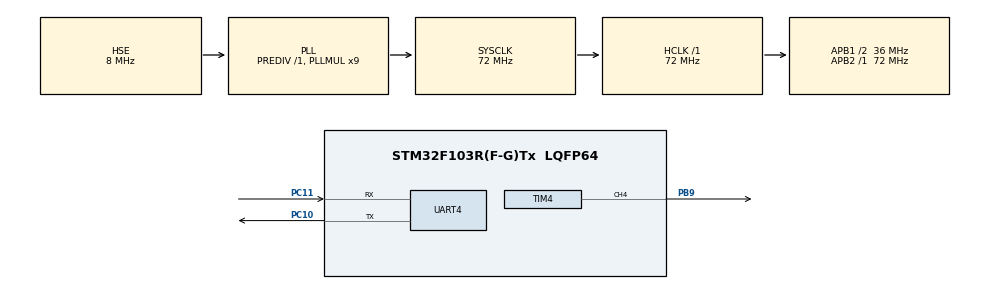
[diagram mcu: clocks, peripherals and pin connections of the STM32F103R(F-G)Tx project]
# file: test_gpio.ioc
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ADC1.Channel-0\#ChannelRegularConversion=ADC_CHANNEL_TEMPSENSOR
ADC1.NbrOfConversionFlag=1
ADC1.Rank-0\#ChannelRegularConversion=1
ADC1.SamplingTime-0\#ChannelRegularConversion=ADC_SAMPLETIME_1CYCLE_5
ADC1.master=1
Dma.Request0=UART4_RX
Dma.Request1=UART4_TX
Dma.UART4_RX.0.Direction=DMA_PERIPH_TO_MEMORY
Dma.UART4_RX.0.Instance=DMA2_Channel3
Dma.UART4_RX.0.MemDataAlignment=DMA_MDATAALIGN_BYTE
Dma.UART4_RX.0.MemInc=DMA_MINC_ENABLE
Dma.UART4_RX.0.Mode=DMA_CIRCULAR
Dma.UART4_RX.0.PeriphDataAlignment=DMA_PDATAALIGN_BYTE
Dma.UART4_RX.0.PeriphInc=DMA_PINC_DISABLE
Dma.UART4_RX.0.Priority=DMA_PRIORITY_LOW
Dma.UART4_TX.1.Direction=DMA_MEMORY_TO_PERIPH
Dma.UART4_TX.1.Instance=DMA2_Channel5
Dma.UART4_TX.1.MemDataAlignment=DMA_MDATAALIGN_BYTE
Dma.UART4_TX.1.MemInc=DMA_MINC_ENABLE
Dma.UART4_TX.1.Mode=DMA_NORMAL
Dma.UART4_TX.1.PeriphDataAlignment=DMA_PDATAALIGN_BYTE
Dma.UART4_TX.1.PeriphInc=DMA_PINC_DISABLE
Dma.UART4_TX.1.Priority=DMA_PRIORITY_LOW
Mcu.Family=STM32F1
Mcu.Name=STM32F103R(F-G)Tx
Mcu.Package=LQFP64
NVIC.DMA2_Channel3_IRQn=true\:0\:0\:false\:false\:true\:false\:true\:true
NVIC.DMA2_Channel4_5_IRQn=true\:0\:0\:false\:false\:true\:false\:true\:true
NVIC.PriorityGroup=NVIC_PRIORITYGROUP_4
NVIC.TIM4_IRQn=true\:0\:0\:false\:false\:true\:true\:true\:true
NVIC.UART4_IRQn=true\:0\:0\:false\:false\:true\:true\:true\:true
PA13.Mode=Serial_Wire
PA13.Signal=SYS_JTMS-SWDIO
PA14.Mode=Serial_Wire
PA14.Signal=SYS_JTCK-SWCLK
PB9.Signal=S_TIM4_CH4
PC10.Mode=Asynchronous
PC10.Signal=UART4_TX
PC11.Mode=Asynchronous
PC11.Signal=UART4_RX
PD0-OSC_IN.Mode=HSE-External-Oscillator
PD0-OSC_IN.Signal=RCC_OSC_IN
PD1-OSC_OUT.Mode=HSE-External-Oscillator
PD1-OSC_OUT.Signal=RCC_OSC_OUT
ProjectManager.HeapSize=0x800
ProjectManager.StackSize=0x1000
ProjectManager.TargetToolchain=STM32CubeIDE
RCC.ADCPresc=RCC_ADCPCLK2_DIV6
RCC.AHBFreq_Value=72000000
RCC.APB1CLKDivider=RCC_HCLK_DIV2
RCC.APB1Freq_Value=36000000
RCC.APB1TimFreq_Value=72000000
RCC.APB2Freq_Value=72000000
RCC.APB2TimFreq_Value=72000000
RCC.HCLKFreq_Value=72000000
RCC.PLLMUL=RCC_PLL_MUL9
RCC.PLLSourceVirtual=RCC_PLLSOURCE_HSE
RCC.SYSCLKFreq_VALUE=72000000
RCC.SYSCLKSource=RCC_SYSCLKSOURCE_PLLCLK
RCC.USBFreq_Value=72000000
SH.S_TIM4_CH4.0=TIM4_CH4,Output Compare4 CH4
TIM4.Channel-Output\ Compare4\ CH4=TIM_CHANNEL_4
TIM4.OC4Preload=DISABLE
TIM4.OCMode_4=TIM_OCMODE_TOGGLE
TIM4.OCPolarity_4=TIM_OCPOLARITY_LOW
TIM4.Period=9999
TIM4.Prescaler=7199
TIM4.Pulse-Output\ Compare4\ CH4=5000
UART4.VirtualMode=Asynchronous
VP_ADC1_TempSens_Input.Mode=IN-TempSens
VP_TIM4_VS_ClockSourceINT.Mode=Internal
board=custom

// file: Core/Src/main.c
/* USER CODE BEGIN Header */
/**
  ******************************************************************************
  * @file           : main.c
  * @brief          : Main program body
  ******************************************************************************
  * @attention
  *
  * Copyright (c) 2026 STMicroelectronics.
  * All rights reserved.
  *
  * This software is licensed under terms that can be found in the LICENSE file
  * in the root directory of this software component.
  * If no LICENSE file comes with this software, it is provided AS-IS.
  *
  ******************************************************************************
  */
/* USER CODE END Header */
#include "main.h"

/* USER CODE BEGIN Includes */
#include <stdio.h>
#include "my_own.h"
/* USER CODE END Includes */

/* USER CODE BEGIN PD */

int tx_ready = 1;
int rx_ready = 0;
uint16_t rx_length = 0;
int uart4_idle = 0;
uint8_t rx_buffer[10];
uint8_t tx_buffer[10];

/* USER CODE END PD */

ADC_HandleTypeDef hadc1;

TIM_HandleTypeDef htim4;

UART_HandleTypeDef huart4;
DMA_HandleTypeDef hdma_uart4_rx;
DMA_HandleTypeDef hdma_uart4_tx;

void SystemClock_Config(void);
static void MX_GPIO_Init(void);
static void MX_DMA_Init(void);
static void MX_UART4_Init(void);
static void MX_ADC1_Init(void);
static void MX_TIM4_Init(void);

int main(void)
{

  /* MCU Configuration--------------------------------------------------------*/

  /* Reset of all peripherals, Initializes the Flash interface and the Systick. */
  HAL_Init();

  /* Configure the system clock */
  SystemClock_Config();

  /* Initialize all configured peripherals */
  MX_GPIO_Init();
  MX_DMA_Init();
  MX_UART4_Init();
  MX_ADC1_Init();
  MX_TIM4_Init();

  /* Infinite loop */
  /* USER CODE BEGIN WHILE */
  const char* msg = "hello from chao dma1\n\r";

//   HAL_UART_Receive_DMA(&huart4, rx_buffer, 10);
//  __HAL_UART_ENABLE_IT(&huart4, UART_IT_IDLE);
   HAL_UARTEx_ReceiveToIdle_DMA(&huart4, rx_buffer, 10);
//   __HAL_DMA_DISABLE_IT(huart4.hdmarx, DMA_IT_HT);

//   start_timer(&htim4);
   HAL_TIM_OC_Start(&htim4, TIM_CHANNEL_4);
  while (1)
  {
    /* USER CODE END WHILE */

    /* USER CODE BEGIN 3 */
//	  static int i = 0;
//
//	  adc_start(&hadc1);
//
//	  gpio_toggle(GPIOB, GPIO_PIN_9);
//
//	  uint32_t value = convert_to_value(adc_read(&hadc1));
//	  uint32_t temp = get_temp(value);
//	  uint32_t x = temp/100;
//	  uint32_t z = temp%100;
//	  printf("chao: %lu.%lu\r\n",x,z);
//	  adc_start(&hadc1);
	  delay(1000);

//	//	  ++i;
//	//	 	 HAL_UART_Transmit(&huart4, (const uint8_t*)(msg), strlen(msg), 100);
//	//	 		  // Receive data: waits up to 1000ms for 10 bytes
//	////	 		  HAL_UART_Receive(&huart4, rx_buffer, 10, 10000);
//	////	 		  HAL_UART_Transmit(&huart4, rx_buffer, 10, 100);
//			 if (tx_ready)
//			 {
//				tx_ready = 0;
//			//	snprintf(tx_buffer, 10, "c:%f\n\r", 2.3f);
//				printf("chao %f\r\n",18.8);
//				printf("chao %d\r\n",18);
//	//	 		 HAL_UART_Transmit(&huart4, "x", 1, 10);
//	//	 		HAL_UART_Transmit_DMA(&huart4, (uint8_t*)tx_buffer, 10);
//				HAL_UART_Transmit_DMA(&huart4, (uint8_t*)msg, strlen(msg));
//			 }
//	//	 	 if (rx_ready && rx_length != 0)
//	//	 	 {
//	//	 		rx_ready = 0;
//	//	 		HAL_UART_Transmit_DMA(&huart4, (uint8_t*)tx_buffer, rx_length);
//	//	 	 }
//
//		  HAL_GPIO_WritePin(GPIOB, GPIO_PIN_9, GPIO_PIN_SET);

  }
  /* USER CODE END 3 */
}

void SystemClock_Config(void)
{
  RCC_OscInitTypeDef RCC_OscInitStruct = {0};
  RCC_ClkInitTypeDef RCC_ClkInitStruct = {0};
  RCC_PeriphCLKInitTypeDef PeriphClkInit = {0};

  /** Initializes the RCC Oscillators according to the specified parameters
  * in the RCC_OscInitTypeDef structure.
  */
  RCC_OscInitStruct.OscillatorType = RCC_OSCILLATORTYPE_HSE;
  RCC_OscInitStruct.HSEState = RCC_HSE_ON;
  RCC_OscInitStruct.HSEPredivValue = RCC_HSE_PREDIV_DIV1;
  RCC_OscInitStruct.HSIState = RCC_HSI_ON;
  RCC_OscInitStruct.PLL.PLLState = RCC_PLL_ON;
  RCC_OscInitStruct.PLL.PLLSource = RCC_PLLSOURCE_HSE;
  RCC_OscInitStruct.PLL.PLLMUL = RCC_PLL_MUL9;
  if (HAL_RCC_OscConfig(&RCC_OscInitStruct) != HAL_OK)
  {
    Error_Handler();
  }

  /** Initializes the CPU, AHB and APB buses clocks
  */
  RCC_ClkInitStruct.ClockType = RCC_CLOCKTYPE_HCLK|RCC_CLOCKTYPE_SYSCLK
                              |RCC_CLOCKTYPE_PCLK1|RCC_CLOCKTYPE_PCLK2;
  RCC_ClkInitStruct.SYSCLKSource = RCC_SYSCLKSOURCE_PLLCLK;
  RCC_ClkInitStruct.AHBCLKDivider = RCC_SYSCLK_DIV1;
  RCC_ClkInitStruct.APB1CLKDivider = RCC_HCLK_DIV2;
  RCC_ClkInitStruct.APB2CLKDivider = RCC_HCLK_DIV1;

  if (HAL_RCC_ClockConfig(&RCC_ClkInitStruct, FLASH_LATENCY_2) != HAL_OK)
  {
    Error_Handler();
  }
  PeriphClkInit.PeriphClockSelection = RCC_PERIPHCLK_ADC;
  PeriphClkInit.AdcClockSelection = RCC_ADCPCLK2_DIV6;
  if (HAL_RCCEx_PeriphCLKConfig(&PeriphClkInit) != HAL_OK)
  {
    Error_Handler();
  }
}

static void MX_ADC1_Init(void)
{

  ADC_ChannelConfTypeDef sConfig = {0};

  /** Common config
  */
  hadc1.Instance = ADC1;
  hadc1.Init.ScanConvMode = ADC_SCAN_DISABLE;
  hadc1.Init.ContinuousConvMode = DISABLE;
  hadc1.Init.DiscontinuousConvMode = DISABLE;
  hadc1.Init.ExternalTrigConv = ADC_SOFTWARE_START;
  hadc1.Init.DataAlign = ADC_DATAALIGN_RIGHT;
  hadc1.Init.NbrOfConversion = 1;
  if (HAL_ADC_Init(&hadc1) != HAL_OK)
  {
    Error_Handler();
  }

  /** Configure Regular Channel
  */
  sConfig.Channel = ADC_CHANNEL_TEMPSENSOR;
  sConfig.Rank = ADC_REGULAR_RANK_1;
  sConfig.SamplingTime = ADC_SAMPLETIME_1CYCLE_5;
  if (HAL_ADC_ConfigChannel(&hadc1, &sConfig) != HAL_OK)
  {
    Error_Handler();
  }

}

static void MX_TIM4_Init(void)
{

  TIM_ClockConfigTypeDef sClockSourceConfig = {0};
  TIM_MasterConfigTypeDef sMasterConfig = {0};
  TIM_OC_InitTypeDef sConfigOC = {0};

  htim4.Instance = TIM4;
  htim4.Init.Prescaler = 7199;
  htim4.Init.CounterMode = TIM_COUNTERMODE_UP;
  htim4.Init.Period = 9999;
  htim4.Init.ClockDivision = TIM_CLOCKDIVISION_DIV1;
  htim4.Init.AutoReloadPreload = TIM_AUTORELOAD_PRELOAD_DISABLE;
  if (HAL_TIM_Base_Init(&htim4) != HAL_OK)
  {
    Error_Handler();
  }
  sClockSourceConfig.ClockSource = TIM_CLOCKSOURCE_INTERNAL;
  if (HAL_TIM_ConfigClockSource(&htim4, &sClockSourceConfig) != HAL_OK)
  {
    Error_Handler();
  }
  if (HAL_TIM_OC_Init(&htim4) != HAL_OK)
  {
    Error_Handler();
  }
  sMasterConfig.MasterOutputTrigger = TIM_TRGO_RESET;
  sMasterConfig.MasterSlaveMode = TIM_MASTERSLAVEMODE_DISABLE;
  if (HAL_TIMEx_MasterConfigSynchronization(&htim4, &sMasterConfig) != HAL_OK)
  {
    Error_Handler();
  }
  sConfigOC.OCMode = TIM_OCMODE_TOGGLE;
  sConfigOC.Pulse = 5000;
  sConfigOC.OCPolarity = TIM_OCPOLARITY_LOW;
  sConfigOC.OCFastMode = TIM_OCFAST_DISABLE;
  if (HAL_TIM_OC_ConfigChannel(&htim4, &sConfigOC, TIM_CHANNEL_4) != HAL_OK)
  {
    Error_Handler();
  }
  HAL_TIM_MspPostInit(&htim4);

}

static void MX_UART4_Init(void)
{

  huart4.Instance = UART4;
  huart4.Init.BaudRate = 115200;
  huart4.Init.WordLength = UART_WORDLENGTH_8B;
  huart4.Init.StopBits = UART_STOPBITS_1;
  huart4.Init.Parity = UART_PARITY_NONE;
  huart4.Init.Mode = UART_MODE_TX_RX;
  huart4.Init.HwFlowCtl = UART_HWCONTROL_NONE;
  huart4.Init.OverSampling = UART_OVERSAMPLING_16;
  if (HAL_UART_Init(&huart4) != HAL_OK)
  {
    Error_Handler();
  }

}

static void MX_DMA_Init(void)
{

  /* DMA controller clock enable */
  __HAL_RCC_DMA2_CLK_ENABLE();

  /* DMA interrupt init */
  /* DMA2_Channel3_IRQn interrupt configuration */
  HAL_NVIC_SetPriority(DMA2_Channel3_IRQn, 0, 0);
  HAL_NVIC_EnableIRQ(DMA2_Channel3_IRQn);
  /* DMA2_Channel4_5_IRQn interrupt configuration */
  HAL_NVIC_SetPriority(DMA2_Channel4_5_IRQn, 0, 0);
  HAL_NVIC_EnableIRQ(DMA2_Channel4_5_IRQn);

}

static void MX_GPIO_Init(void)
{

  /* GPIO Ports Clock Enable */
  __HAL_RCC_GPIOD_CLK_ENABLE();
  __HAL_RCC_GPIOA_CLK_ENABLE();
  __HAL_RCC_GPIOC_CLK_ENABLE();
  __HAL_RCC_GPIOB_CLK_ENABLE();

}

/* USER CODE BEGIN 4 */
void HAL_UART_TxCpltCallback(UART_HandleTypeDef *huart) {
    if (huart->Instance == UART4) {
        tx_ready = 1; // Hardware is free again!
    }
}
//void HAL_UART_RxCpltCallback(UART_HandleTypeDef *huart) {
//    if (huart->Instance == UART4) {
//        rx_ready = 1; // Hardware is free again!
//    }
//}
//void HAL_UARTEx_RxEventCallback(UART_HandleTypeDef *huart, uint16_t Size)
//{
//	if (huart->Instance == UART4)
//	{
//	    rx_ready = 1; // Hardware is free again!
//	    rx_length = Size;
//	    memcpy(tx_buffer, rx_buffer, rx_length);
//	    HAL_UARTEx_ReceiveToIdle_DMA(&huart4, rx_buffer, 10);
//	    __HAL_DMA_DISABLE_IT(huart->hdmarx, DMA_IT_HT);
//
//	}
//}
/* USER CODE END 4 */

void Error_Handler(void)
{
  __disable_irq();
  while (1)
  {
  }
}
